# nRF7140_graphics register map
Vendor: Nordic Semiconductor; Series: nRF71; File version: 1
CPU: CM33 r0p4, little endian, MPU, FPU, 3 interrupt priority bits, 480 interrupts
Registers are 32-bit, read-write, reset 0x0 unless marked. A register's access mark holds for its fields unless they carry their own. Offsets are from the block's base; [hi:lo] are bit positions; lines under a group give offsets from that group; {n}, {i} and the like mark numbered series; 'fields as' and 'values as' point back to an identical list.

## MEMCONF_NS — Memory configuration
Base 0x49011000
{0x500+0x10*i} POWER[{i}] (i=0..1) group — Unspecified
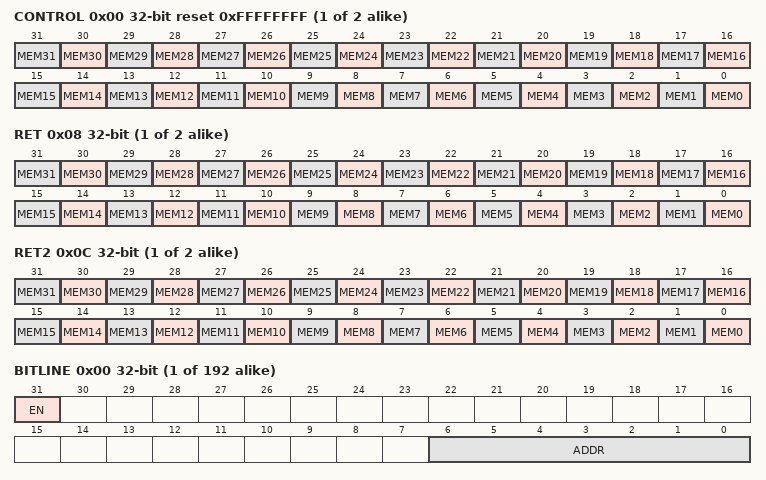
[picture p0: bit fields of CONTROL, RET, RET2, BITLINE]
  0x00 CONTROL reset 0xFFFFFFFF — Description cluster: RAM/ROM[n] power control register.
    [all] fields
      0=Off (Power down); 1=On (Power up)
    [n] MEM{n} (n=0..31) — Keep the RAM/ROM block MEM[{n}] on or off when in System ON mode.
  0x08 RET — Description cluster: RAM retention for RAM [n].
    [all] fields
      0=Off (Retention off); 1=On (Retention on)
    [n] MEM{n} (n=0..31) — Keep the RAM block MEM[{n}] retained when in System OFF mode.
  0x0C RET2 — Description cluster: RAM retention for the second bank in the RAM block
    [all] fields
      0=Off (Retention off); 1=On (Retention on)
    [n] MEM{n} (n=0..31) — Keep the second bank in RAM block MEM[{n}] retained when in System OFF mode.
{0x600+4i} REPAIR[{i}] (i=0..191) group — Unspecified
  0x00 BITLINE — Description cluster: Repair configuration for RAM blocks.
    [31] EN — Enable bitline repair
      0=Disabled (Repair disabled.); 1=Enabled (Repair enabled.)
    [6:0] ADDR — Repair address of the bitline
{0x900+4i} BLOCKTYPE[{i}] (i=0..63) group — Unspecified
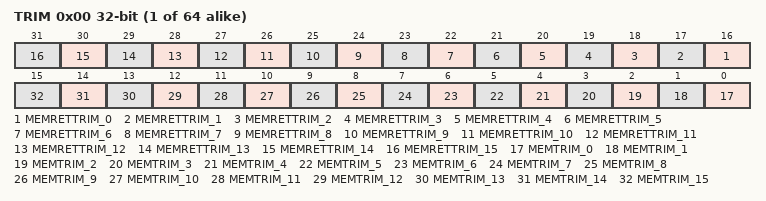
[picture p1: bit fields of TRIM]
  0x00 TRIM — Description cluster: Trim configuration for the RAM/ROM block types.
    [n+16] MEMRETTRIM_{n} (n=0..15) — Trimming for retention mode for decreased leakage. Must be kept active in RAM retention mode.
    [n] MEMTRIM_{n} (n=0..15) — Read/write margin trim.

## PCGCS_NS — PCGCSlave
Base 0x4901D000
{0xC00+4i} PENALTY[{i}] (i=0..1) — Description collection: Penalty level for power/clock pair n
  [7:0] PENALTY — Penalty level
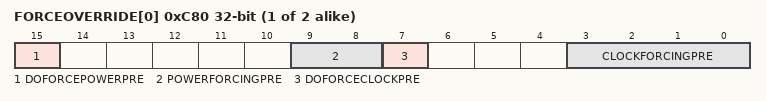
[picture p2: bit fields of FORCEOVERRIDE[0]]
{0xC80+4i} FORCEOVERRIDE[{i}] (i=0..1) — Description collection: Force override of power/clock pair n
  [15] DOFORCEPOWERPRE, [9:8] POWERFORCINGPRE, [7] DOFORCECLOCKPRE, [3:0] CLOCKFORCINGPRE

## GLOBAL_TBM_NS — Trace buffer monitor 0
Base 0xBF003000
Same registers: GLOBAL_TBM_S 0xBF003000 (alternate view of GLOBAL_TBM_NS)
0x00 TASKS_START wo — Start counter
  [0] TASKS_START
    1=Trigger task
0x04 TASKS_STOP wo — Stop counter, clear counter value
  [0] TASKS_STOP
    1=Trigger task
0x08 TASKS_FLUSH wo — Stop counter, keep current counter value
  [0] TASKS_FLUSH
    1=Trigger task
0x100 EVENTS_HALFFULL — Counter value equals half-full
  [0] EVENTS_HALFFULL
    0=NotGenerated (Event not generated); 1=Generated (Event generated)
0x104 EVENTS_FULL — Counter value equals full
  [0] EVENTS_FULL
    values as EVENTS_HALFFULL.EVENTS_HALFFULL
0x108 EVENTS_FLUSH — Counter stopped due to flush
  [0] EVENTS_FLUSH
    values as EVENTS_HALFFULL.EVENTS_HALFFULL
0x200 SHORTS — Shortcuts between local events and tasks
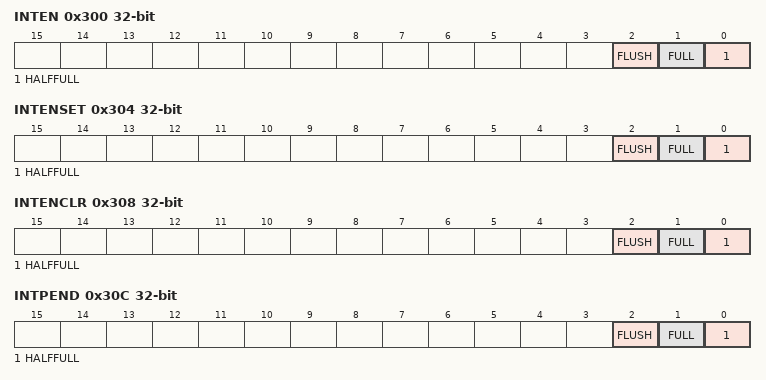
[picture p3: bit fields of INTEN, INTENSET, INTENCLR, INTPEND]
0x300 INTEN — Enable or disable interrupt
  [all] fields
    0=Disabled; 1=Enabled
  [2] FLUSH — Enable or disable interrupt for event FLUSH
  [1] FULL — Enable or disable interrupt for event FULL
  [0] HALFFULL — Enable or disable interrupt for event HALFFULL
0x304 INTENSET — Enable interrupt
  [all] fields
    on read: 0=Disabled (Read: Disabled); 1=Enabled (Read: Enabled) | on write: 1=Set (Enable)
  [2] FLUSH — Write '1' to enable interrupt for event FLUSH
  [1] FULL — Write '1' to enable interrupt for event FULL
  [0] HALFFULL — Write '1' to enable interrupt for event HALFFULL
0x308 INTENCLR — Disable interrupt
  [all] fields
    on read: 0=Disabled (Read: Disabled); 1=Enabled (Read: Enabled) | on write: 1=Clear (Disable)
  [2] FLUSH — Write '1' to disable interrupt for event FLUSH
  [1] FULL — Write '1' to disable interrupt for event FULL
  [0] HALFFULL — Write '1' to disable interrupt for event HALFFULL
0x30C INTPEND ro — Pending interrupts
  [all] fields
    on read: 0=NotPending (Read: Not pending); 1=Pending (Read: Pending)
  [2] FLUSH — Read pending status of interrupt for event FLUSH
  [1] FULL — Read pending status of interrupt for event FULL
  [0] HALFFULL — Read pending status of interrupt for event HALFFULL
0x400 BUFFERSIZE reset 0x1FF — System RAM trace buffer total size in bytes
  [11:0] BUFFERSIZE — Must only be configured in STOP mode. Must be multiple of 16 bytes to make half-buffer size always 64 bit word aligned. BUFFERSIZE LSB byte always fixed as 0xF to 16 bytes boundary. Minimum BUFFERSIZE value 0x00F i.e. 16 bytes, maximum value 0xFFF i.e. 4096 bytes.
    15=Min (16 bytes); 0xFFF=Max (4096 bytes)
0x404 COUNT ro — Counter current value
  [11:0] COUNT
